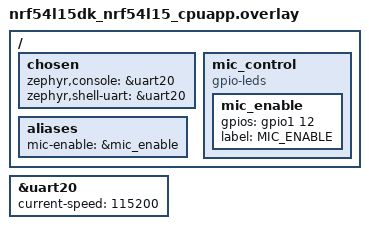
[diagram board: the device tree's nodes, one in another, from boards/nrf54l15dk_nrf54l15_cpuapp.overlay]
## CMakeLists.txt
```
# SPDX-License-Identifier: Apache-2.0
# Cochlear Implant Project - DSP Applications
# Target: nRF54L15

cmake_minimum_required(VERSION 3.20.0)

find_package(Zephyr REQUIRED HINTS $ENV{ZEPHYR_BASE})
project(cochlear_implant_dsp)

# Build option: select which application to build
# BUILD_APP options:
#   "hearing_aid_dsp" - Hearing Aid DSP Signal Processor (default)
#   "fft_analyzer"    - FFT Waveform Analyzer
#   "pdm_test"        - PDM Microphone Test
set(BUILD_APP "hearing_aid_dsp" CACHE STRING "Application to build")
set_property(CACHE BUILD_APP PROPERTY STRINGS "hearing_aid_dsp" "fft_analyzer" "pdm_test")

if(BUILD_APP STREQUAL "hearing_aid_dsp")
    message(STATUS "Building Hearing Aid DSP Processor (12-band WDRC + BLE)")
    target_sources(app PRIVATE
        src/hearing_aid_dsp.c
        src/ble_service.c
    )
elseif(BUILD_APP STREQUAL "fft_analyzer")
    message(STATUS "Building FFT Waveform Analyzer v1.0")
    target_sources(app PRIVATE
        src/fft_waveform_v1.c
    )
else()
    message(STATUS "Building PDM Microphone Test")
    target_sources(app PRIVATE
        src/main.c
    )
endif()

# Math library for FFT/DSP calculations
target_link_libraries(app PRIVATE m)
```

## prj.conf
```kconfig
# SPDX-License-Identifier: Apache-2.0
# Project Configuration for Cochlear Implant DSP Applications
# Target: nRF54L15

# =============================================================================
# Logging Configuration
# =============================================================================
CONFIG_LOG=y
CONFIG_LOG_DEFAULT_LEVEL=3
CONFIG_LOG_BACKEND_UART=y
CONFIG_LOG_MODE_IMMEDIATE=y

# =============================================================================
# Console/UART Configuration
# =============================================================================
CONFIG_CONSOLE=y
CONFIG_UART_CONSOLE=y
CONFIG_PRINTK=y
CONFIG_SERIAL=y
CONFIG_UART_INTERRUPT_DRIVEN=y

# Increase UART buffer for audio data transfer
CONFIG_UART_0_NRF_TX_BUFFER_SIZE=256

# =============================================================================
# Audio/PDM Configuration (for microphone integration)
# =============================================================================
CONFIG_AUDIO=y
CONFIG_AUDIO_DMIC=y
CONFIG_NRFX_PDM=y

# =============================================================================
# GPIO Configuration
# =============================================================================
CONFIG_GPIO=y

# =============================================================================
# Memory Configuration for DSP Processing + BLE
# =============================================================================
CONFIG_HEAP_MEM_POOL_SIZE=65536
CONFIG_MAIN_STACK_SIZE=32768
CONFIG_SYSTEM_WORKQUEUE_STACK_SIZE=4096

# =============================================================================
# Floating Point Support
# =============================================================================
CONFIG_FPU=y
CONFIG_FPU_SHARING=y
CONFIG_CBPRINTF_FP_SUPPORT=y

# =============================================================================
# C Library (required for math functions)
# =============================================================================
CONFIG_NEWLIB_LIBC=y
CONFIG_NEWLIB_LIBC_NANO=n

# =============================================================================
# Debugging Support
# =============================================================================
CONFIG_USE_SEGGER_RTT=y
CONFIG_RTT_CONSOLE=n

# =============================================================================
# Bluetooth Low Energy Configuration
# =============================================================================
CONFIG_BT=y
CONFIG_BT_PERIPHERAL=y
CONFIG_BT_DEVICE_NAME="BoneCond HA"
CONFIG_BT_DEVICE_APPEARANCE=0x0941
CONFIG_BT_MAX_CONN=1
CONFIG_BT_GATT_DYNAMIC_DB=n
CONFIG_BT_ATT_TX_COUNT=10
CONFIG_BT_L2CAP_TX_BUF_COUNT=10
CONFIG_BT_BUF_ACL_RX_SIZE=502
CONFIG_BT_BUF_ACL_TX_SIZE=502
CONFIG_BT_CTLR_DATA_LENGTH_MAX=251
CONFIG_BT_USER_DATA_LEN_UPDATE=y

# =============================================================================
# Performance Optimizations
# =============================================================================
CONFIG_SPEED_OPTIMIZATIONS=y
```

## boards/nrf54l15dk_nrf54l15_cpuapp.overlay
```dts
/*
 * SPDX-License-Identifier: Apache-2.0
 *
 * Device Tree Overlay for nRF54L15-DK
 * Cochlear Implant Project - PDM Microphone Configuration
 *
 * Adjust pin assignments to match your hardware setup.
 */

/ {
    chosen {
        /* Use UART for console output */
        zephyr,console = &uart20;
        zephyr,shell-uart = &uart20;
    };
};

/* UART configuration for serial output */
&uart20 {
    status = "okay";
    current-speed = <115200>;
};

/*
 * Infineon IM69D129F PDM Microphone Pin Configuration
 * 
 * Wiring to nRF54L15-DK:
 * - IM69D129F CLK  -> P1.10 (PDM clock, 1.28 MHz)
 * - IM69D129F DATA -> P1.11 (PDM data)
 * - IM69D129F VDD  -> 1.8V (supports 1.62V - 3.6V)
 * - IM69D129F GND  -> GND
 * - IM69D129F L/R  -> GND (falling edge) or VDD (rising edge)
 *
 * Note: The nrfx_pdm driver is configured in main.c
 * This overlay is for reference and any additional peripherals.
 */

/*
 * GPIO configuration for optional mic power control
 * Some MEMS mics have an enable pin
 */
/ {
    mic_control {
        compatible = "gpio-leds";
        mic_enable: mic_enable {
            /* Adjust pin as needed for your hardware */
            gpios = <&gpio1 12 GPIO_ACTIVE_HIGH>;
            label = "MIC_ENABLE";
        };
    };

    aliases {
        mic-enable = &mic_enable;
    };
};
```

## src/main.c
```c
/*
 * SPDX-License-Identifier: Apache-2.0
 *
 * Cochlear Implant Project - PDM Microphone Waveform Test
 * Target: nRF54L15
 *
 * This skeleton reads PDM microphone data and outputs the waveform
 * to the serial console for visualization.
 */

#include <zephyr/kernel.h>
#include <zephyr/logging/log.h>
#include <zephyr/device.h>
#include <zephyr/drivers/gpio.h>
#include <nrfx_pdm.h>
#include <string.h>
#include <math.h>

LOG_MODULE_REGISTER(mic_test, LOG_LEVEL_INF);

/*
 * =============================================================================
 * Configuration - Infineon IM69D129F PDM Microphone
 * =============================================================================
 *
 * IM69D129F Key Specifications:
 * - SNR: 69 dB (A-weighted)
 * - AOP: 128 dB SPL (high dynamic range - great for hearing aids)
 * - Sensitivity: -36 dBFS @ 94 dB SPL
 * - PDM Clock: 1.0 MHz to 3.25 MHz (optimal ~2.4 MHz)
 * - Supply: 1.62V to 3.6V
 * - Current: ~650 µA active
 *
 * L/R Pin Configuration:
 * - L/R = LOW (GND):  Data valid on FALLING edge (Left channel timing)
 * - L/R = HIGH (VDD): Data valid on RISING edge (Right channel timing)
 */

/* PDM pin configuration - adjust these for your hardware */
#define PDM_CLK_PIN     NRF_GPIO_PIN_MAP(1, 10)  /* P1.10 - PDM Clock */
#define PDM_DATA_PIN    NRF_GPIO_PIN_MAP(1, 11)  /* P1.11 - PDM Data */

/*
 * IM69D129F L/R pin configuration:
 * Set to 1 if L/R pin is tied HIGH (data on rising edge)
 * Set to 0 if L/R pin is tied LOW (data on falling edge)
 */
#define IM69D129_LR_HIGH    0

/* Audio sample configuration */
#define SAMPLE_RATE_HZ      16000   /* 16 kHz sample rate */
#define AUDIO_BUFFER_SAMPLES 256    /* Samples per buffer */
#define NUM_BUFFERS         2       /* Double buffering */

/* Waveform display configuration */
#define WAVEFORM_WIDTH      64      /* ASCII waveform width in characters */
#define DISPLAY_INTERVAL_MS 100     /* How often to update display */
#define DOWNSAMPLE_FACTOR   8       /* Reduce samples for display */

/*
 * =============================================================================
 * Audio Buffers
 * =============================================================================
 */

static int16_t audio_buffer_0[AUDIO_BUFFER_SAMPLES];
static int16_t audio_buffer_1[AUDIO_BUFFER_SAMPLES];
static int16_t *current_buffer = audio_buffer_0;
static volatile bool buffer_ready = false;
static volatile uint8_t active_buffer = 0;

/*
 * =============================================================================
 * PDM Event Handler
 * =============================================================================
 */

static void pdm_event_handler(nrfx_pdm_evt_t const *p_evt)
{
    if (p_evt->error != NRFX_PDM_NO_ERROR) {
        LOG_ERR("PDM error: %d", p_evt->error);
        return;
    }

    if (p_evt->buffer_released != NULL) {
        /* A buffer has been filled and released */
        current_buffer = (int16_t *)p_evt->buffer_released;
        buffer_ready = true;
    }

    if (p_evt->buffer_requested) {
        /* PDM driver needs a new buffer - provide the next one */
        int16_t *next_buffer;
        if (active_buffer == 0) {
            next_buffer = audio_buffer_1;
            active_buffer = 1;
        } else {
            next_buffer = audio_buffer_0;
            active_buffer = 0;
        }
        
        nrfx_err_t err = nrfx_pdm_buffer_set(next_buffer, AUDIO_BUFFER_SAMPLES);
        if (err != NRFX_SUCCESS) {
            LOG_ERR("Failed to set PDM buffer: 0x%x", err);
        }
    }
}

/*
 * =============================================================================
 * PDM Initialization
 * =============================================================================
 */

static int pdm_init(void)
{
    nrfx_err_t err;

    /*
     * Configure PDM for Infineon IM69D129F
     *
     * Clock frequency selection:
     * - IM69D129F supports 1.0 - 3.25 MHz, optimal around 2.4 MHz
     * - NRF_PDM_FREQ_1280K = 1.28 MHz (good balance of quality/power)
     * - NRF_PDM_FREQ_1067K = 1.067 MHz (lower power)
     * 
     * With RATIO_80X and 1.28 MHz clock: sample rate = 1.28M / 80 = 16 kHz
     * With RATIO_64X and 1.024 MHz clock: sample rate = 1.024M / 64 = 16 kHz
     *
     * Edge selection based on L/R pin:
     * - L/R LOW:  Use NRF_PDM_EDGE_LEFTFALLING
     * - L/R HIGH: Use NRF_PDM_EDGE_LEFTRISING
     */
    nrfx_pdm_config_t pdm_config = {
        .mode = NRF_PDM_MODE_MONO,
#if IM69D129_LR_HIGH
        .edge = NRF_PDM_EDGE_LEFTRISING,   /* L/R pin HIGH: data on rising edge */
#else
        .edge = NRF_PDM_EDGE_LEFTFALLING,  /* L/R pin LOW: data on falling edge */
#endif
        .clk_pin = PDM_CLK_PIN,
        .din_pin = PDM_DATA_PIN,
        .clock_freq = NRF_PDM_FREQ_1280K,  /* 1.28 MHz - within IM69D129F range */
        .gain_l = NRF_PDM_GAIN_DEFAULT,    /* 0 dB gain - IM69D129F has good sensitivity */
        .gain_r = NRF_PDM_GAIN_DEFAULT,
        .ratio = NRF_PDM_RATIO_80X,        /* 1.28 MHz / 80 = 16 kHz sample rate */
        .skip_gpio_cfg = false,
        .skip_psel_cfg = false,
    };

    /* Initialize PDM driver */
    err = nrfx_pdm_init(&pdm_config, pdm_event_handler);
    if (err != NRFX_SUCCESS) {
        LOG_ERR("PDM init failed: 0x%x", err);
        return -EIO;
    }

    LOG_INF("PDM initialized for Infineon IM69D129F");
    LOG_INF("  Clock: 1.28 MHz, Sample rate: %d Hz", SAMPLE_RATE_HZ);
#if IM69D129_LR_HIGH
    LOG_INF("  L/R config: HIGH (rising edge)");
#else
    LOG_INF("  L/R config: LOW (falling edge)");
#endif
    return 0;
}

/*
 * =============================================================================
 * PDM Start/Stop
 * =============================================================================
 */

static int pdm_start(void)
{
    nrfx_err_t err;

    /* Set initial buffer */
    err = nrfx_pdm_buffer_set(audio_buffer_0, AUDIO_BUFFER_SAMPLES);
    if (err != NRFX_SUCCESS) {
        LOG_ERR("Failed to set initial PDM buffer: 0x%x", err);
        return -EIO;
    }

    /* Start PDM sampling */
    err = nrfx_pdm_start();
    if (err != NRFX_SUCCESS) {
        LOG_ERR("PDM start failed: 0x%x", err);
        return -EIO;
    }

    LOG_INF("PDM started - sampling at %d Hz", SAMPLE_RATE_HZ);
    return 0;
}

/*
 * =============================================================================
 * Waveform Display Functions
 * =============================================================================
 */

/**
 * Calculate audio statistics from buffer
 */
static void calculate_audio_stats(int16_t *buffer, size_t len, 
                                   int16_t *min, int16_t *max, int32_t *avg)
{
    *min = INT16_MAX;
    *max = INT16_MIN;
    int64_t sum = 0;

    for (size_t i = 0; i < len; i++) {
        if (buffer[i] < *min) *min = buffer[i];
        if (buffer[i] > *max) *max = buffer[i];
        sum += buffer[i];
    }

    *avg = (int32_t)(sum / len);
}

/**
 * Calculate RMS (Root Mean Square) level - useful for audio level metering
 */
static uint32_t calculate_rms(int16_t *buffer, size_t len)
{
    uint64_t sum_sq = 0;
    
    for (size_t i = 0; i < len; i++) {
        int32_t sample = buffer[i];
        sum_sq += (sample * sample);
    }
    
    return (uint32_t)sqrt((double)sum_sq / len);
}

/**
 * Print an ASCII waveform to the console
 */
static void print_waveform(int16_t *buffer, size_t len)
{
    char line[WAVEFORM_WIDTH + 3];  /* +3 for '|' chars and null terminator */
    
    /* Clear screen and move cursor to top (ANSI escape) */
    printk("\033[2J\033[H");
    
    printk("=== PDM Microphone Waveform Test ===\n");
    printk("Sample Rate: %d Hz | Buffer: %d samples\n\n", 
           SAMPLE_RATE_HZ, AUDIO_BUFFER_SAMPLES);

    /* Calculate statistics */
    int16_t min, max;
    int32_t avg;
    calculate_audio_stats(buffer, len, &min, &max, &avg);
    uint32_t rms = calculate_rms(buffer, len);

    printk("Stats: Min=%6d  Max=%6d  Avg=%6d  RMS=%5u\n\n", 
           min, max, avg, rms);

    /* Print ASCII waveform - downsample for display */
    printk("Waveform (downsampled %dx):\n", DOWNSAMPLE_FACTOR);
    
    size_t display_samples = len / DOWNSAMPLE_FACTOR;
    if (display_samples > WAVEFORM_WIDTH) {
        display_samples = WAVEFORM_WIDTH;
    }

    /* Normalize samples to 0-WAVEFORM_WIDTH range for display */
    int16_t range = max - min;
    if (range == 0) range = 1;  /* Avoid division by zero */

    /* Print top border */
    printk("+");
    for (int i = 0; i < WAVEFORM_WIDTH; i++) printk("-");
    printk("+\n");

    /* Print waveform as vertical bars centered around middle */
    const int height = 16;  /* ASCII waveform height */
    
    for (int row = height - 1; row >= 0; row--) {
        printk("|");
        
        for (size_t col = 0; col < display_samples; col++) {
            size_t idx = col * DOWNSAMPLE_FACTOR;
            
            /* Normalize sample to 0-height range */
            int normalized = ((buffer[idx] - min) * height) / range;
            
            if (normalized >= row) {
                printk("#");
            } else {
                printk(" ");
            }
        }
        
        /* Pad remaining columns */
        for (size_t col = display_samples; col < WAVEFORM_WIDTH; col++) {
            printk(" ");
        }
        
        printk("|\n");
    }

    /* Print bottom border */
    printk("+");
    for (int i = 0; i < WAVEFORM_WIDTH; i++) printk("-");
    printk("+\n");

    /* Print raw sample values (first few) */
    printk("\nRaw samples (first 16):\n");
    for (int i = 0; i < 16 && i < len; i++) {
        printk("%6d ", buffer[i]);
        if ((i + 1) % 8 == 0) printk("\n");
    }
    printk("\n");

    /* Print level meter */
    printk("\nLevel: [");
    int level_bars = (rms * 32) / 32768;
    if (level_bars > 32) level_bars = 32;
    for (int i = 0; i < 32; i++) {
        if (i < level_bars) {
            if (i < 20) printk("=");
            else if (i < 28) printk("*");
            else printk("!");
        } else {
            printk(" ");
        }
    }
    printk("] %u\n", rms);
}

/**
 * Print raw samples as CSV (useful for plotting in external tools)
 */
static void print_samples_csv(int16_t *buffer, size_t len)
{
    printk("\n--- CSV START ---\n");
    for (size_t i = 0; i < len; i++) {
        printk("%d\n", buffer[i]);
    }
    printk("--- CSV END ---\n");
}

/*
 * =============================================================================
 * Main Application
 * =============================================================================
 */

int main(void)
{
    int ret;

    LOG_INF("Cochlear Implant Project - PDM Microphone Test");
    LOG_INF("Target: nRF54L15");
    LOG_INF("Starting up...");

    /* Small delay for system stabilization */
    k_sleep(K_MSEC(100));

    /* Initialize PDM */
    ret = pdm_init();
    if (ret < 0) {
        LOG_ERR("Failed to initialize PDM microphone!");
        LOG_ERR("Check pin configuration:");
        LOG_ERR("  CLK: P%d.%d", PDM_CLK_PIN >> 5, PDM_CLK_PIN & 0x1F);
        LOG_ERR("  DATA: P%d.%d", PDM_DATA_PIN >> 5, PDM_DATA_PIN & 0x1F);
        return ret;
    }

    /* Start PDM sampling */
    ret = pdm_start();
    if (ret < 0) {
        LOG_ERR("Failed to start PDM!");
        return ret;
    }

    LOG_INF("PDM microphone running - displaying waveform...");
    LOG_INF("Press any key to output CSV format");

    /* Main loop - display waveform when buffer is ready */
    uint32_t frame_count = 0;
    bool csv_mode = false;

    while (1) {
        if (buffer_ready) {
            buffer_ready = false;
            frame_count++;

            if (csv_mode) {
                /* Output raw CSV for external analysis */
                print_samples_csv(current_buffer, AUDIO_BUFFER_SAMPLES);
                k_sleep(K_MSEC(1000));  /* Slower rate for CSV */
            } else {
                /* Display ASCII waveform */
                print_waveform(current_buffer, AUDIO_BUFFER_SAMPLES);
            }

            /* Log periodic status */
            if (frame_count % 100 == 0) {
                LOG_INF("Processed %u audio frames", frame_count);
            }
        }

        /* Small delay to prevent busy-waiting */
        k_sleep(K_MSEC(DISPLAY_INTERVAL_MS));
    }

    return 0;
}
```

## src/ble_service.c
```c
/*
 * SPDX-License-Identifier: Apache-2.0
 *
 * Cochlear Implant Project - BLE GATT Service for Hearing Aid Configuration
 * Target: nRF54L15
 *
 * Provides a custom GATT service that allows a host application to read/write
 * DSP configuration parameters over Bluetooth Low Energy. The same binary
 * protocol used over UART is tunneled through BLE characteristics.
 */

#include <zephyr/kernel.h>
#include <zephyr/logging/log.h>
#include <zephyr/bluetooth/bluetooth.h>
#include <zephyr/bluetooth/hci.h>
#include <zephyr/bluetooth/conn.h>
#include <zephyr/bluetooth/uuid.h>
#include <zephyr/bluetooth/gatt.h>
#include <string.h>

LOG_MODULE_REGISTER(ble_service, LOG_LEVEL_INF);

/*
 * =============================================================================
 * External: command handler defined in hearing_aid_dsp.c
 * =============================================================================
 */
extern void handle_config_command(uint8_t cmd, uint8_t *payload, uint16_t len);

/*
 * =============================================================================
 * Custom Service UUIDs
 * =============================================================================
 * Service:         12345678-1234-5678-1234-56789abcdef0
 * Config Write:    12345678-1234-5678-1234-56789abcdef1
 * Config Notify:   12345678-1234-5678-1234-56789abcdef2
 */

#define HA_SERVICE_UUID_VAL \
    BT_UUID_128_ENCODE(0x12345678, 0x1234, 0x5678, 0x1234, 0x56789abcdef0)

#define HA_CONFIG_WRITE_UUID_VAL \
    BT_UUID_128_ENCODE(0x12345678, 0x1234, 0x5678, 0x1234, 0x56789abcdef1)

#define HA_CONFIG_NOTIFY_UUID_VAL \
    BT_UUID_128_ENCODE(0x12345678, 0x1234, 0x5678, 0x1234, 0x56789abcdef2)

static struct bt_uuid_128 ha_service_uuid = BT_UUID_INIT_128(HA_SERVICE_UUID_VAL);
static struct bt_uuid_128 ha_config_write_uuid = BT_UUID_INIT_128(HA_CONFIG_WRITE_UUID_VAL);
static struct bt_uuid_128 ha_config_notify_uuid = BT_UUID_INIT_128(HA_CONFIG_NOTIFY_UUID_VAL);

/*
 * =============================================================================
 * BLE State
 * =============================================================================
 */

static bool ble_connected = false;
static bool notify_enabled = false;
static struct bt_conn *current_conn = NULL;

/* Buffer for assembling multi-packet writes */
#define BLE_RX_BUFFER_SIZE 512
static uint8_t ble_rx_buffer[BLE_RX_BUFFER_SIZE];
static size_t ble_rx_pos = 0;
static size_t ble_rx_expected = 0;
static uint8_t ble_rx_cmd = 0;

/* Buffer for sending responses via notify */
#define BLE_TX_BUFFER_SIZE 512
static uint8_t ble_tx_buffer[BLE_TX_BUFFER_SIZE];

/*
 * =============================================================================
 * BLE Response Sending (via Notification)
 * =============================================================================
 */

/* Forward declaration of the GATT service for notification */
static struct bt_gatt_attr ha_service_attrs[];

void ble_send_response(const uint8_t *data, size_t len)
{
    if (!ble_connected || !notify_enabled || !current_conn) {
        return;
    }

    if (len > BLE_TX_BUFFER_SIZE) {
        LOG_WRN("BLE response too large: %d bytes", len);
        return;
    }

    memcpy(ble_tx_buffer, data, len);

    /* Attribute for notify characteristic (index 4 in service: svc, write_decl, write_val, notify_decl, notify_val, ccc) */
    struct bt_gatt_notify_params params = {
        .attr = &ha_service_attrs[4],
        .data = ble_tx_buffer,
        .len = len,
    };

    int err = bt_gatt_notify_cb(current_conn, &params);
    if (err) {
        LOG_WRN("BLE notify failed: %d", err);
    }
}

/*
 * =============================================================================
 * Config Write Characteristic Handler
 * =============================================================================
 * Receives protocol frames: [cmd:1][len:2 LE][payload:N]
 * Reassembles multi-packet writes for large payloads.
 */

static ssize_t config_write_handler(struct bt_conn *conn,
                                     const struct bt_gatt_attr *attr,
                                     const void *buf, uint16_t len,
                                     uint16_t offset, uint8_t flags)
{
    const uint8_t *data = buf;

    if (ble_rx_pos == 0 && len >= 3) {
        /* Start of a new command frame */
        ble_rx_cmd = data[0];
        ble_rx_expected = data[1] | ((uint16_t)data[2] << 8);

        if (ble_rx_expected == 0) {
            /* Commands with empty payload (R, S) */
            handle_config_command(ble_rx_cmd, NULL, 0);
            return len;
        }

        if (ble_rx_expected > BLE_RX_BUFFER_SIZE) {
            LOG_ERR("BLE payload too large: %d", ble_rx_expected);
            ble_rx_pos = 0;
            return len;
        }

        /* Copy remaining bytes after the 3-byte header */
        size_t payload_in_this_packet = len - 3;
        if (payload_in_this_packet > ble_rx_expected) {
            payload_in_this_packet = ble_rx_expected;
        }
        memcpy(ble_rx_buffer, &data[3], payload_in_this_packet);
        ble_rx_pos = payload_in_this_packet;

    } else if (ble_rx_pos > 0) {
        /* Continuation of a multi-packet write */
        size_t remaining = ble_rx_expected - ble_rx_pos;
        size_t to_copy = (len < remaining) ? len : remaining;
        memcpy(&ble_rx_buffer[ble_rx_pos], data, to_copy);
        ble_rx_pos += to_copy;
    }

    /* Check if we have received the full payload */
    if (ble_rx_pos >= ble_rx_expected && ble_rx_expected > 0) {
        handle_config_command(ble_rx_cmd, ble_rx_buffer, ble_rx_expected);
        ble_rx_pos = 0;
        ble_rx_expected = 0;
    }

    return len;
}

/*
 * =============================================================================
 * Notify CCC (Client Characteristic Configuration) Changed
 * =============================================================================
 */

static void notify_ccc_changed(const struct bt_gatt_attr *attr, uint16_t value)
{
    notify_enabled = (value == BT_GATT_CCC_NOTIFY);
    LOG_INF("BLE notifications %s", notify_enabled ? "enabled" : "disabled");
}

/*
 * =============================================================================
 * GATT Service Definition
 * =============================================================================
 */

BT_GATT_SERVICE_DEFINE(ha_service,
    /* Primary Service */
    BT_GATT_PRIMARY_SERVICE(&ha_service_uuid),

    /* Config Write Characteristic */
    BT_GATT_CHARACTERISTIC(&ha_config_write_uuid.uuid,
                           BT_GATT_CHRC_WRITE | BT_GATT_CHRC_WRITE_WITHOUT_RESP,
                           BT_GATT_PERM_WRITE,
                           NULL, config_write_handler, NULL),

    /* Config Notify Characteristic */
    BT_GATT_CHARACTERISTIC(&ha_config_notify_uuid.uuid,
                           BT_GATT_CHRC_NOTIFY,
                           BT_GATT_PERM_NONE,
                           NULL, NULL, NULL),
    BT_GATT_CCC(notify_ccc_changed,
                 BT_GATT_PERM_READ | BT_GATT_PERM_WRITE),
);

/* Save reference to service attrs for notify calls */
static struct bt_gatt_attr *ha_service_attrs = ha_service.attrs;

/*
 * =============================================================================
 * BLE Connection Callbacks
 * =============================================================================
 */

static void connected(struct bt_conn *conn, uint8_t err)
{
    if (err) {
        LOG_ERR("BLE connection failed (err %u)", err);
        return;
    }

    LOG_INF("BLE connected");
    ble_connected = true;
    current_conn = bt_conn_ref(conn);

    /* Request higher MTU for large config transfers */
    struct bt_conn_info info;
    bt_conn_get_info(conn, &info);
}

static void disconnected(struct bt_conn *conn, uint8_t reason)
{
    LOG_INF("BLE disconnected (reason %u)", reason);
    ble_connected = false;
    notify_enabled = false;
    ble_rx_pos = 0;

    if (current_conn) {
        bt_conn_unref(current_conn);
        current_conn = NULL;
    }
}

BT_CONN_CB_DEFINE(conn_callbacks) = {
    .connected = connected,
    .disconnected = disconnected,
};

/*
 * =============================================================================
 * Advertising Data
 * =============================================================================
 */

static const struct bt_data ad[] = {
    BT_DATA_BYTES(BT_DATA_FLAGS, (BT_LE_AD_GENERAL | BT_LE_AD_NO_BREDR)),
    BT_DATA_BYTES(BT_DATA_UUID128_ALL, HA_SERVICE_UUID_VAL),
};

static const struct bt_data sd[] = {
    BT_DATA(BT_DATA_NAME_COMPLETE, CONFIG_BT_DEVICE_NAME, sizeof(CONFIG_BT_DEVICE_NAME) - 1),
};

/*
 * =============================================================================
 * BLE Initialization
 * =============================================================================
 */

int ble_service_init(void)
{
    int err;

    err = bt_enable(NULL);
    if (err) {
        LOG_ERR("Bluetooth init failed (err %d)", err);
        return err;
    }

    LOG_INF("Bluetooth initialized");

    err = bt_le_adv_start(BT_LE_ADV_CONN, ad, ARRAY_SIZE(ad), sd, ARRAY_SIZE(sd));
    if (err) {
        LOG_ERR("Advertising failed to start (err %d)", err);
        return err;
    }

    LOG_INF("BLE advertising started as \"%s\"", CONFIG_BT_DEVICE_NAME);
    return 0;
}

bool ble_is_connected(void)
{
    return ble_connected;
}
```
